# ESP32-P4 register map
Vendor: ESPRESSIF SYSTEMS (SHANGHAI) CO., LTD.; Series: ESP32 P-Series; File version: 3
CPU: RV32IMAFC r0p0, little endian, no MPU, FPU, 0 interrupt priority bits
Address unit: 32 bits
Registers are 32-bit, read-write, reset 0x0 unless marked. A register's access mark holds for its fields unless they carry their own. Offsets are from the block's base; [hi:lo] are bit positions; lines under a group give offsets from that group; {n}, {i} and the like mark numbered series.

## MCPWM0 — Motor Control Pulse-Width Modulation 0
Base 0x500C0000
Same registers: MCPWM1 0x500C1000
0x00 CLK_CFG — PWM clock prescaler register.
  [7:0] CLK_PRESCALE — Configures the prescaler value of clock, so that the period of PWM_clk = 6.25ns * (PWM_CLK_PRESCALE + 1).
{0x4+0x10*i} TIMER{i} (i=0..2) group — Cluster TIMER{i}, containing TIMER?_CFG0, TIMER?_CFG1, TIMER?_SYNC, TIMER?_STATUS
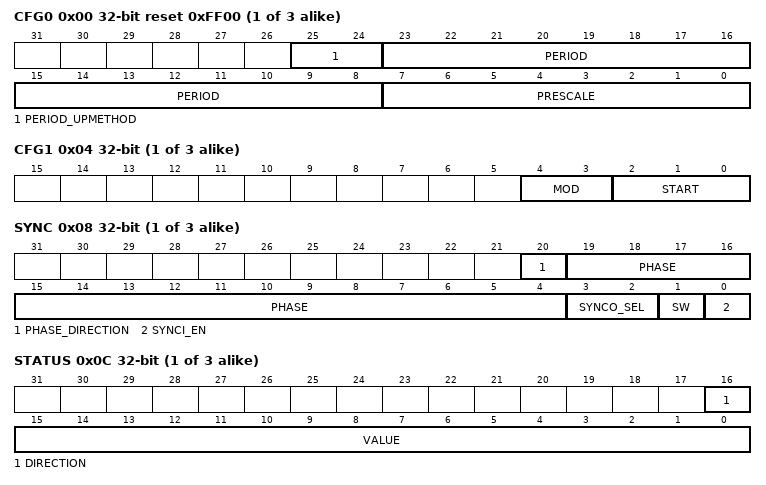
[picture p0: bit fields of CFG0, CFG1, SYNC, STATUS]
  0x00 CFG0 reset 0xFF00 — PWM timer0 period and update method configuration register.
    [25:24] PERIOD_UPMETHOD — Configures the update method for active register of PWM timer%s period.\\0: Immediate\\1: TEZ\\2: Sync\\3: TEZ or sync\\TEZ here and below means timer equal zero event
    [23:8] PERIOD — Configures the period shadow of PWM timer%s
    [7:0] PRESCALE — Configures the prescaler value of timer%s, so that the period of PT0_clk = Period of PWM_clk * (PWM_TIMER%s_PRESCALE + 1)
  0x04 CFG1 — PWM timer0 working mode and start/stop control register.
    [4:3] MOD — Configures the working mode of PWM timer%s.\\0: Freeze\\1: Increase mode\\2: Decrease mode\\3: Up-down mode
    [2:0] START — Configures whether or not to start/stop PWM timer%s.\\0: If PWM timer%s starts, then stops at TEZ\\1: If timer%s starts, then stops at TEP\\2: PWM timer%s starts and runs on\\3: Timer%s starts and stops at the next TEZ\\4: Timer0 starts and stops at the next TEP.\\TEP here and below means the event that happens when the timer equals to period
  0x08 SYNC — PWM timer0 sync function configuration register.
    [20] PHASE_DIRECTION — Configures the PWM timer%s's direction when timer%s mode is up-down mode.\\0: Increase\\1: Decrease
    [19:4] PHASE — Configures the phase for timer%s reload on sync event.
    [3:2] SYNCO_SEL — Configures the selection of PWM timer%s sync_out.\\0: Sync_in\\1: TEZ\\2: TEP\\3: Invalid, sync_out selects noting
    [1] SW — Configures the generation of software sync. Toggling this bit will trigger a software sync.
    [0] SYNCI_EN — Configures whether or not to enable timer%s reloading with phase on sync input event is enabled.\\0: Disable\\1: Enable
  0x0C STATUS ro — PWM timer0 status register.
    [16] DIRECTION — Represents current PWM timer%s counter direction.\\0: Increment\\1: Decrement
    [15:0] VALUE — Represents current PWM timer%s counter value.
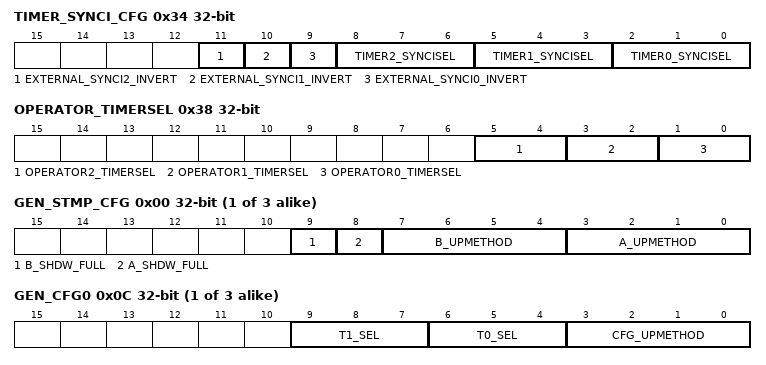
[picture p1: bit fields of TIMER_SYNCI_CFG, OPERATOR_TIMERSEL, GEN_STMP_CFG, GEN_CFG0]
0x34 TIMER_SYNCI_CFG — Synchronization input selection register for PWM timers.
  [11] EXTERNAL_SYNCI2_INVERT — Configures whether or not to invert SYNC2 from GPIO matrix.\\0: Not invert\\1: Invert
  [10] EXTERNAL_SYNCI1_INVERT — Configures whether or not to invert SYNC1 from GPIO matrix.\\0: Not invert\\1: Invert
  [9] EXTERNAL_SYNCI0_INVERT — Configures whether or not to invert SYNC0 from GPIO matrix.\\0: Not invert\\1: Invert
  [8:6] TIMER2_SYNCISEL — Configures the selection of sync input for PWM timer2.\\1: PWM timer0 sync_out\\2: PWM timer1 sync_out\\3: PWM timer2 sync_out\\4: SYNC0 from GPIO matrix\\5: SYNC1 from GPIO matrix\\6: SYNC2 from GPIO matrix\\Other values: No sync input selected
  [5:3] TIMER1_SYNCISEL — Configures the selection of sync input for PWM timer1.\\1: PWM timer0 sync_out\\2: PWM timer1 sync_out\\3: PWM timer2 sync_out\\4: SYNC0 from GPIO matrix\\5: SYNC1 from GPIO matrix\\6: SYNC2 from GPIO matrix\\Other values: No sync input selected
  [2:0] TIMER0_SYNCISEL — Configures the selection of sync input for PWM timer0.\\1: PWM timer0 sync_out\\2: PWM timer1 sync_out\\3: PWM timer2 sync_out\\4: SYNC0 from GPIO matrix\\5: SYNC1 from GPIO matrix\\6: SYNC2 from GPIO matrix\\Other values: No sync input selected
0x38 OPERATOR_TIMERSEL — PWM operator's timer select register
  [5:4] OPERATOR2_TIMERSEL — Configures which PWM timer will be the timing reference for PWM operator2.\\0: Timer0\\1: Timer1\\2: Timer2\\3: Invalid, will select timer2
  [3:2] OPERATOR1_TIMERSEL — Configures which PWM timer will be the timing reference for PWM operator1.\\0: Timer0\\1: Timer1\\2: Timer2\\3: Invalid, will select timer2
  [1:0] OPERATOR0_TIMERSEL — Configures which PWM timer will be the timing reference for PWM operator0.\\0: Timer0\\1: Timer1\\2: Timer2\\3: Invalid, will select timer2
{0x3C+0x38*i} CH{i} (i=0..2) group — Cluster CH{i}, containing GEN?_STMP_CFG, GEN?_TSTMP_A, GEN?_TSTMP_B, GEN?_CFG0, GEN?_FORCE, GEN?_A, GEN?_B, DT?_CFG, DT?_FED_CFG, DT?_RED_CFG, CARRIER?_CFG, FH?_CFG0, FH?_CFG1, FH?_STATUS
  0x00 GEN_STMP_CFG — Generator0 time stamp registers A and B transfer status and update method register
    [9] B_SHDW_FULL — Represents whether or not generator%s time stamp B's shadow reg is transferred.\\0: B's active reg has been updated with shadow register latest value.\\1: B's shadow reg is filled and waiting to be transferred to B's active reg
    [8] A_SHDW_FULL — Represents whether or not generator%s time stamp A's shadow reg is transferred.\\0: A's active reg has been updated with shadow register latest value.\\1: A's shadow reg is filled and waiting to be transferred to A's active reg
    [7:4] B_UPMETHOD — Configures the update method for PWM generator %s time stamp B's active register.\\0: Immediately\\Bit0 is set to 1: TEZ\\Bit1 is set to 1: TEP\\Bit2 is set to 1: Sync\\Bit3 is set to 1: Disable the update
    [3:0] A_UPMETHOD — Configures the update method for PWM generator %s time stamp A's active register.\\0: Immediately\\Bit0 is set to 1: TEZ\\Bit1 is set to 1: TEP\\Bit2 is set to 1: Sync\\Bit3 is set to 1: Disable the update
  0x04 GEN_TSTMP_A — Generator0 time stamp A's shadow register
    [15:0] A — Configures the value of PWM generator %s time stamp A's shadow register.
  0x08 GEN_TSTMP_B — Generator0 time stamp B's shadow register
    [15:0] B — Configures the value of PWM generator %s time stamp B's shadow register.
  0x0C GEN_CFG0 — Generator0 fault event T0 and T1 configuration register
    [9:7] T1_SEL — Configures source selection for PWM generator %s event_t1, take effect immediately.\\0: fault_event0\\1: fault_event1\\2: fault_event2\\3: sync_taken\\4: Invalid, Select nothing
    [6:4] T0_SEL — Configures source selection for PWM generator %s event_t0, take effect immediately.\\0: fault_event0\\1: fault_event1\\2: fault_event2\\3: sync_taken\\4: Invalid, Select nothing
    [3:0] CFG_UPMETHOD — Configures update method for PWM generator %s's active register.\\0: Immediately\\Bit0 is set to 1: TEZ\\Bit1 is set to 1: TEP\\Bit2 is set to 1: Sync\\Bit3 is set to 1: Disable the update
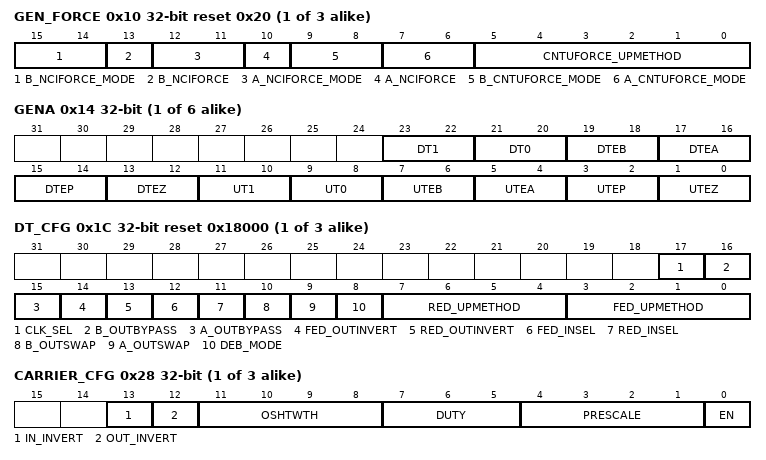
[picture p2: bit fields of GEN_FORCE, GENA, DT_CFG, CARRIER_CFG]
  0x10 GEN_FORCE reset 0x20 — Generator0 output signal force mode register.
    [15:14] B_NCIFORCE_MODE — Configures non-continuous immediate software force mode for PWM%s B.\\0: Disabled\\1: Low\\2: High\\3: Disabled
    [13] B_NCIFORCE — Configures the generation of non-continuous immediate software-force event for PWM%s B, a toggle will trigger a force event.
    [12:11] A_NCIFORCE_MODE — Configures non-continuous immediate software force mode for PWM%s A.\\0: Disabled\\1: Low\\2: High\\3: Disabled
    [10] A_NCIFORCE — Configures the generation of non-continuous immediate software-force event for PWM%s A, a toggle will trigger a force event.
    [9:8] B_CNTUFORCE_MODE — Configures continuous software force mode for PWM%s B.\\0: Disabled\\1: Low\\2: High\\3: Disabled
    [7:6] A_CNTUFORCE_MODE — Configures continuous software force mode for PWM%s A.\\0: Disabled\\1: Low\\2: High\\3: Disabled
    [5:0] CNTUFORCE_UPMETHOD — Configures update method for continuous software force of PWM generator%s.\\0: Immediately\\Bit0 is set to 1: TEZ\\Bit1 is set to 1: TEP\\Bit2 is set to 1: TEA\\Bit3 is set to 1: TEB\\Bit4 is set to 1: Sync\\Bit5 is set to 1: Disable update. TEA/B here and below means an event generated when the timer's value equals to that of register A/B.
  0x14 GEN{x} (x=A,B; step 0x4) — Actions triggered by events on PWMx{x}
    [23:22] DT1 — Configures action on PWM%s A triggered by event_t1 when timer decreasing.\\0: No change\\1: Low\\2: High\\3: Toggle
    [21:20] DT0 — Configures action on PWM%s A triggered by event_t0 when timer decreasing.\\0: No change\\1: Low\\2: High\\3: Toggle
    [19:18] DTEB — Configures action on PWM%s A triggered by event TEB when timer decreasing.\\0: No change\\1: Low\\2: High\\3: Toggle
    [17:16] DTEA — Configures action on PWM%s A triggered by event TEA when timer decreasing.\\0: No change\\1: Low\\2: High\\3: Toggle
    [15:14] DTEP — Configures action on PWM%s A triggered by event TEP when timer decreasing.\\0: No change\\1: Low\\2: High\\3: Toggle
    [13:12] DTEZ — Configures action on PWM%s A triggered by event TEZ when timer decreasing.\\0: No change\\1: Low\\2: High\\3: Toggle
    [11:10] UT1 — Configures action on PWM%s A triggered by event_t1 when timer increasing.\\0: No change\\1: Low\\2: High\\3: Toggle
    [9:8] UT0 — Configures action on PWM%s A triggered by event_t0 when timer increasing.\\0: No change\\1: Low\\2: High\\3: Toggle
    [7:6] UTEB — Configures action on PWM%s A triggered by event TEB when timer increasing.\\0: No change\\1: Low\\2: High\\3: Toggle
    [5:4] UTEA — Configures action on PWM%s A triggered by event TEA when timer increasing.\\0: No change\\1: Low\\2: High\\3: Toggle
    [3:2] UTEP — Configures action on PWM%s A triggered by event TEP when timer increasing.\\0: No change\\1: Low\\2: High\\3: Toggle
    [1:0] UTEZ — Configures action on PWM%s A triggered by event TEZ when timer increasing.\\0: No change\\1: Low\\2: High\\3: Toggle
  0x1C DT_CFG reset 0x18000 — Dead time configuration register
    [17] CLK_SEL — Configures dead time generator %s clock selection.\\0: PWM_clk\\1: PT_clk
    [16] B_OUTBYPASS — Configures S0 in table.
    [15] A_OUTBYPASS — Configures S1 in table.
    [14] FED_OUTINVERT — Configures S3 in table.
    [13] RED_OUTINVERT — Configures S2 in table.
    [12] FED_INSEL — Configures S5 in table.
    [11] RED_INSEL — Configures S4 in table.
    [10] B_OUTSWAP — Configures S7 in table.
    [9] A_OUTSWAP — Configures S6 in table.
    [8] DEB_MODE — Configures S8 in table, dual-edge B mode.\\0: fed/red take effect on different path separately\\1: fed/red take effect on B path, A out is in bypass or dulpB mode
    [7:4] RED_UPMETHOD — Configures update method for RED (rising edge delay) active register.\\0: Immediate\\Bit0 is set to 1: TEZ\\Bit1 is set to 1: TEP\\Bit2 is set to 1: Sync\\Bit3 is set to 1: Disable the update
    [3:0] FED_UPMETHOD — Configures update method for FED (Falling edge delay) active register.\\0: Immediate\\Bit0 is set to 1: TEZ\\Bit1 is set to 1: TEP\\Bit2 is set to 1: Sync\\Bit3 is set to 1: Disable the update
  0x20 DT_FED_CFG — Falling edge delay (FED) shadow register
    [15:0] FED — Configures shadow register for FED.
  0x24 DT_RED_CFG — Rising edge delay (RED) shadow register
    [15:0] RED — Configures shadow register for RED.
  0x28 CARRIER_CFG — Carrier0 configuration register
    [13] IN_INVERT — Configures whether or not to invert the input of PWM%s A and PWM%s B for this submodule.\\0: Normal\\1: Invert
    [12] OUT_INVERT — Configures whether or not to invert the output of PWM%s A and PWM%s B for this submodule.\\0: Normal\\1: Invert
    [11:8] OSHTWTH — Configures width of the first pulse. Measurement unit: Periods of the carrier.
    [7:5] DUTY — Configures carrier duty. Duty = PWM_CARRIER%s_DUTY / 8
    [4:1] PRESCALE — Configures the prescale value of PWM carrier%s clock (PC_clk), so that period of PC_clk = period of PWM_clk * (PWM_CARRIER%s_PRESCALE + 1)
    [0] EN — Configures whether or not to enable carrier%s.\\0: Bypassed\\1: Enabled
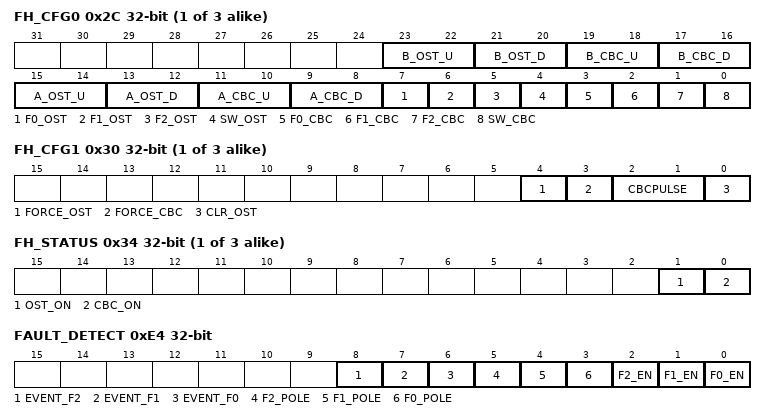
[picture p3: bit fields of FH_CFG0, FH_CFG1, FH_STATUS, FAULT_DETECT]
  0x2C FH_CFG0 — PWM0 A and PWM0 B trip events actions configuration register
    [23:22] B_OST_U — Configures one-shot mode action on PWM%s B when fault event occurs and timer is increasing.\\0: Do nothing\\1: Force low\\2: Force high\\3: Toggle
    [21:20] B_OST_D — Configures one-shot mode action on PWM%s B when fault event occurs and timer is decreasing.\\0: Do nothing\\1: Force low\\2: Force high\\3: Toggle
    [19:18] B_CBC_U — Configures cycle-by-cycle mode action on PWM%s B when fault event occurs and timer is increasing.\\0: Do nothing\\1: Force low\\2: Force high\\3: Toggle
    [17:16] B_CBC_D — Configures cycle-by-cycle mode action on PWM%s B when fault event occurs and timer is decreasing.\\0: Do nothing\\1: Force low\\2: Force high\\3: Toggle
    [15:14] A_OST_U — Configures one-shot mode action on PWM%s A when fault event occurs and timer is increasing.\\0: Do nothing\\1: Force low\\2: Force high\\3: Toggle
    [13:12] A_OST_D — Configures one-shot mode action on PWM%s A when fault event occurs and timer is decreasing.\\0: Do nothing\\1: Force low\\2: Force high\\3: Toggle
    [11:10] A_CBC_U — Configures cycle-by-cycle mode action on PWM%s A when fault event occurs and timer is increasing.\\0: Do nothing\\1: Force low\\2: Force high\\3: Toggle
    [9:8] A_CBC_D — Configures cycle-by-cycle mode action on PWM%s A when fault event occurs and timer is decreasing.\\0: Do nothing\\1: Force low\\2: Force high\\3: Toggle
    [7] F0_OST — Configures whether or not event_f0 will trigger one-shot mode action.\\0: Disable\\1: Enable
    [6] F1_OST — Configures whether or not event_f1 will trigger one-shot mode action.\\0: Disable\\1: Enable
    [5] F2_OST — Configures whether or not event_f2 will trigger one-shot mode action.\\0: Disable\\1: Enable
    [4] SW_OST — Configures whether or not to enable software force one-shot mode action.\\0: Disable\\1: Enable
    [3] F0_CBC — Configures whether or not event_f0 will trigger cycle-by-cycle mode action.\\0: Disable\\1: Enable
    [2] F1_CBC — Configures whether or not event_f1 will trigger cycle-by-cycle mode action.\\0: Disable\\1: Enable
    [1] F2_CBC — Configures whether or not event_f2 will trigger cycle-by-cycle mode action.\\0: Disable\\1: Enable
    [0] SW_CBC — Configures whether or not to enable software force cycle-by-cycle mode action.\\0: Disable\\1: Enable
  0x30 FH_CFG1 — Software triggers for fault handler actions configuration register
    [4] FORCE_OST — Configures the generation of software one-shot mode action. A toggle (software negate its value) triggers a one-shot mode action.
    [3] FORCE_CBC — Configures the generation of software cycle-by-cycle mode action. A toggle (software negate its value) triggers a cycle-by-cycle mode action.
    [2:1] CBCPULSE — Configures the refresh moment selection of cycle-by-cycle mode action.\\0: Select nothing, will not refresh\\Bit0 is set to 1: TEZ\\Bit1 is set to 1: TEP
    [0] CLR_OST — Configures the generation of software one-shot mode action clear. A toggle (software negate its value) triggers a clear for on going one-shot mode action.
  0x34 FH_STATUS ro — Fault events status register
    [1] OST_ON — Represents whether or not an one-shot mode action is on going.\\0:No action\\1: On going
    [0] CBC_ON — Represents whether or not an cycle-by-cycle mode action is on going.\\0:No action\\1: On going
0xE4 FAULT_DETECT access per field — Fault detection configuration and status register
  [8] EVENT_F2 ro — Represents whether or not an event_f2 is on going.\\0: No action\\1: On going
  [7] EVENT_F1 ro — Represents whether or not an event_f1 is on going.\\0: No action\\1: On going
  [6] EVENT_F0 ro — Represents whether or not an event_f0 is on going.\\0: No action\\1: On going
  [5] F2_POLE rw — Configures event_f2 trigger polarity on FAULT2 source from GPIO matrix.\\0: Level low\\1: Level high
  [4] F1_POLE rw — Configures event_f1 trigger polarity on FAULT1 source from GPIO matrix.\\0: Level low\\1: Level high
  [3] F0_POLE rw — Configures event_f0 trigger polarity on FAULT0 source from GPIO matrix.\\0: Level low\\1: Level high
  [2] F2_EN rw — Configures whether or not to enable event_f2 generation.\\0: Disable\\1: Enable
  [1] F1_EN rw — Configures whether or not to enable event_f1 generation.\\0: Disable\\1: Enable
  [0] F0_EN rw — Configures whether or not to enable event_f0 generation.\\0: Disable\\1: Enable
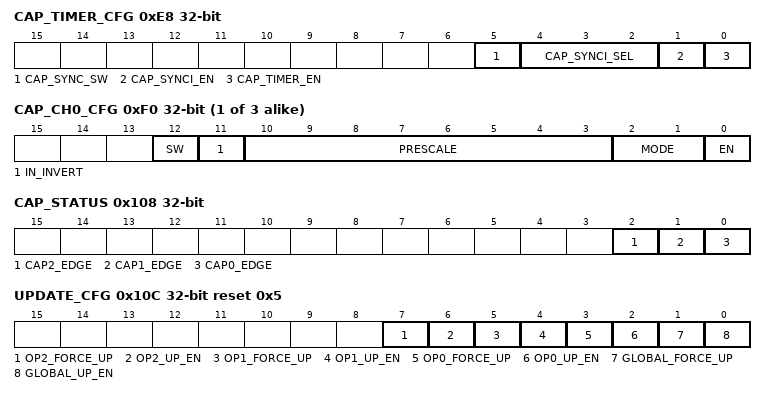
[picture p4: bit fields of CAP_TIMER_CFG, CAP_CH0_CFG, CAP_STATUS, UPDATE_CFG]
0xE8 CAP_TIMER_CFG access per field — Capture timer configuration register
  [5] CAP_SYNC_SW wo — Configures the generation of a capture timer sync when reg_cap_synci_en is 1.\\0: Invalid, No effect\\1: Trigger a capture timer sync, capture timer is loaded with value in phase register
  [4:2] CAP_SYNCI_SEL rw — Configures the selection of capture module sync input.\\0: None\\1: Timer0 sync_out\\2: Timer1 sync_out\\3: Timer2 sync_out\\4: SYNC0 from GPIO matrix\\5: SYNC1 from GPIO matrix\\6: SYNC2 from GPIO matrix\\7: None
  [1] CAP_SYNCI_EN rw — Configures whether or not to enable capture timer sync.\\0: Disable\\1: Enable
  [0] CAP_TIMER_EN rw — Configures whether or not to enable capture timer increment.\\0: Disable\\1: Enable
0xEC CAP_TIMER_PHASE — Capture timer sync phase register
  [31:0] CAP_PHASE — Configures phase value for capture timer sync operation.
{0xF0+4i} CAP_CH{i}_CFG (i=0..2) access per field — Capture channel {i} configuration register
  [12] SW wo — Configures the generation of software capture.\\0: Invalid, No effect\\1: Trigger a software forced capture on channel %s
  [11] IN_INVERT rw — Configures whether or not to invert CAP%s from GPIO matrix before prescale.\\0: Normal\\1: Invert
  [10:3] PRESCALE rw — Configures prescale value on possitive edge of CAP%s. Prescale value = PWM_CAP%s_PRESCALE + 1
  [2:1] MODE rw — Configures which edge of capture on channel %s after prescaling is used.\\0: None\\Bit0 is set to 1: Rnable capture on the negative edge\\Bit1 is set to 1: Enable capture on the positive edge
  [0] EN rw — Configures whether or not to enable capture on channel %s.\\0: Disable\\1: Enable
{0xFC+4i} CAP_CH{i} (i=0..2) ro — CAP{i} capture value register
  [31:0] VALUE — Represents value of last capture on CAP%s
0x108 CAP_STATUS ro — Last capture trigger edge information register
  [2] CAP2_EDGE — Represents edge of last capture trigger on channel2.\\0: Posedge\\1: Negedge
  [1] CAP1_EDGE — Represents edge of last capture trigger on channel1.\\0: Posedge\\1: Negedge
  [0] CAP0_EDGE — Represents edge of last capture trigger on channel0.\\0: Posedge\\1: Negedge
0x10C UPDATE_CFG reset 0x5 — Generator Update configuration register
  [7] OP2_FORCE_UP — Configures the generation of forced update for active registers in PWM operator2. A toggle (software invert its value) will trigger a forced update. Valid only when MCPWM_GLOBAL_UP_EN and MCPWM_OP2_UP_EN are both set to 1.
  [6] OP2_UP_EN — Configures whether or not to enable update of active registers in PWM operator2. Valid only when PWM_GLOBAL_UP_EN is set to 1.\\0: Disable\\1: Enable
  [5] OP1_FORCE_UP — Configures the generation of forced update for active registers in PWM operator1. A toggle (software invert its value) will trigger a forced update. Valid only when MCPWM_GLOBAL_UP_EN and MCPWM_OP1_UP_EN are both set to 1.
  [4] OP1_UP_EN — Configures whether or not to enable update of active registers in PWM operator1. Valid only when PWM_GLOBAL_UP_EN is set to 1.\\0: Disable\\1: Enable
  [3] OP0_FORCE_UP — Configures the generation of forced update for active registers in PWM operator0. A toggle (software invert its value) will trigger a forced update. Valid only when MCPWM_GLOBAL_UP_EN and MCPWM_OP0_UP_EN are both set to 1.
  [2] OP0_UP_EN — Configures whether or not to enable update of active registers in PWM operator0. Valid only when PWM_GLOBAL_UP_EN is set to 1.\\0: Disable\\1: Enable
  [1] GLOBAL_FORCE_UP — Configures the generation of global forced update for all active registers in MCPWM module. A toggle (software invert its value) will trigger a global forced update. Valid only when MCPWM_GLOBAL_UP_EN and MCPWM_OP0/1/2_UP_EN are both set to 1.
  [0] GLOBAL_UP_EN — Configures whether or not to enable global update for all active registers in MCPWM module.\\0: Disable\\1: Enable
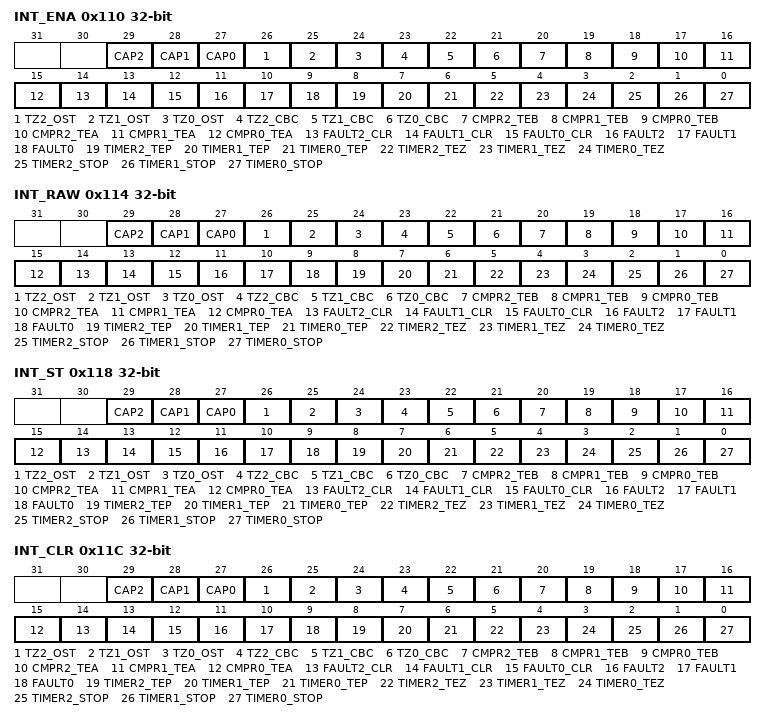
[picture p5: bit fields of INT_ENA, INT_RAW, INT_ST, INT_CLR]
0x110 INT_ENA — Interrupt enable register
  [29] CAP2 — Enable bit: Write 1 to enable the interrupt triggered by capture on CAP2.
  [28] CAP1 — Enable bit: Write 1 to enable the interrupt triggered by capture on CAP1.
  [27] CAP0 — Enable bit: Write 1 to enable the interrupt triggered by capture on CAP0.
  [26] TZ2_OST — Enable bit: Write 1 to enable the interrupt triggered by a one-shot mode action on PWM2.
  [25] TZ1_OST — Enable bit: Write 1 to enable the interrupt triggered by a one-shot mode action on PWM1.
  [24] TZ0_OST — Enable bit: Write 1 to enable the interrupt triggered by a one-shot mode action on PWM0.
  [23] TZ2_CBC — Enable bit: Write 1 to enable the interrupt triggered by a cycle-by-cycle mode action on PWM2.
  [22] TZ1_CBC — Enable bit: Write 1 to enable the interrupt triggered by a cycle-by-cycle mode action on PWM1.
  [21] TZ0_CBC — Enable bit: Write 1 to enable the interrupt triggered by a cycle-by-cycle mode action on PWM0.
  [20] CMPR2_TEB — Enable bit: Write 1 to enable the interrupt triggered by a PWM operator 2 TEB event.
  [19] CMPR1_TEB — Enable bit: Write 1 to enable the interrupt triggered by a PWM operator 1 TEB event.
  [18] CMPR0_TEB — Enable bit: Write 1 to enable the interrupt triggered by a PWM operator 0 TEB event.
  [17] CMPR2_TEA — Enable bit: Write 1 to enable the interrupt triggered by a PWM operator 2 TEA event.
  [16] CMPR1_TEA — Enable bit: Write 1 to enable the interrupt triggered by a PWM operator 1 TEA event.
  [15] CMPR0_TEA — Enable bit: Write 1 to enable the interrupt triggered by a PWM operator 0 TEA event.
  [14] FAULT2_CLR — Enable bit: Write 1 to enable the interrupt triggered when event_f2 clears.
  [13] FAULT1_CLR — Enable bit: Write 1 to enable the interrupt triggered when event_f1 clears.
  [12] FAULT0_CLR — Enable bit: Write 1 to enable the interrupt triggered when event_f0 clears.
  [11] FAULT2 — Enable bit: Write 1 to enable the interrupt triggered when event_f2 starts.
  [10] FAULT1 — Enable bit: Write 1 to enable the interrupt triggered when event_f1 starts.
  [9] FAULT0 — Enable bit: Write 1 to enable the interrupt triggered when event_f0 starts.
  [8] TIMER2_TEP — Enable bit: Write 1 to enable the interrupt triggered by a PWM timer 2 TEP event.
  [7] TIMER1_TEP — Enable bit: Write 1 to enable the interrupt triggered by a PWM timer 1 TEP event.
  [6] TIMER0_TEP — Enable bit: Write 1 to enable the interrupt triggered by a PWM timer 0 TEP event.
  [5] TIMER2_TEZ — Enable bit: Write 1 to enable the interrupt triggered by a PWM timer 2 TEZ event.
  [4] TIMER1_TEZ — Enable bit: Write 1 to enable the interrupt triggered by a PWM timer 1 TEZ event.
  [3] TIMER0_TEZ — Enable bit: Write 1 to enable the interrupt triggered by a PWM timer 0 TEZ event.
  [2] TIMER2_STOP — Enable bit: Write 1 to enable the interrupt triggered when the timer 2 stops.
  [1] TIMER1_STOP — Enable bit: Write 1 to enable the interrupt triggered when the timer 1 stops.
  [0] TIMER0_STOP — Enable bit: Write 1 to enable the interrupt triggered when the timer 0 stops.
0x114 INT_RAW — Interrupt raw status register
  [29] CAP2 — Raw status bit: The raw interrupt status of the interrupt triggered by capture on CAP2.
  [28] CAP1 — Raw status bit: The raw interrupt status of the interrupt triggered by capture on CAP1.
  [27] CAP0 — Raw status bit: The raw interrupt status of the interrupt triggered by capture on CAP0.
  [26] TZ2_OST — Raw status bit: The raw interrupt status of the interrupt triggered by a one-shot mode action on PWM2.
  [25] TZ1_OST — Raw status bit: The raw interrupt status of the interrupt triggered by a one-shot mode action on PWM1.
  [24] TZ0_OST — Raw status bit: The raw interrupt status of the interrupt triggered by a one-shot mode action on PWM0.
  [23] TZ2_CBC — Raw status bit: The raw interrupt status of the interrupt triggered by a cycle-by-cycle mode action on PWM2.
  [22] TZ1_CBC — Raw status bit: The raw interrupt status of the interrupt triggered by a cycle-by-cycle mode action on PWM1.
  [21] TZ0_CBC — Raw status bit: The raw interrupt status of the interrupt triggered by a cycle-by-cycle mode action on PWM0.
  [20] CMPR2_TEB — Raw status bit: The raw interrupt status of the interrupt triggered by a PWM operator 2 TEB event
  [19] CMPR1_TEB — Raw status bit: The raw interrupt status of the interrupt triggered by a PWM operator 1 TEB event
  [18] CMPR0_TEB — Raw status bit: The raw interrupt status of the interrupt triggered by a PWM operator 0 TEB event
  [17] CMPR2_TEA — Raw status bit: The raw interrupt status of the interrupt triggered by a PWM operator 2 TEA event
  [16] CMPR1_TEA — Raw status bit: The raw interrupt status of the interrupt triggered by a PWM operator 1 TEA event
  [15] CMPR0_TEA — Raw status bit: The raw interrupt status of the interrupt triggered by a PWM operator 0 TEA event
  [14] FAULT2_CLR — Raw status bit: The raw interrupt status of the interrupt triggered when event_f2 clears.
  [13] FAULT1_CLR — Raw status bit: The raw interrupt status of the interrupt triggered when event_f1 clears.
  [12] FAULT0_CLR — Raw status bit: The raw interrupt status of the interrupt triggered when event_f0 clears.
  [11] FAULT2 — Raw status bit: The raw interrupt status of the interrupt triggered when event_f2 starts.
  [10] FAULT1 — Raw status bit: The raw interrupt status of the interrupt triggered when event_f1 starts.
  [9] FAULT0 — Raw status bit: The raw interrupt status of the interrupt triggered when event_f0 starts.
  [8] TIMER2_TEP — Raw status bit: The raw interrupt status of the interrupt triggered by a PWM timer 2 TEP event.
  [7] TIMER1_TEP — Raw status bit: The raw interrupt status of the interrupt triggered by a PWM timer 1 TEP event.
  [6] TIMER0_TEP — Raw status bit: The raw interrupt status of the interrupt triggered by a PWM timer 0 TEP event.
  [5] TIMER2_TEZ — Raw status bit: The raw interrupt status of the interrupt triggered by a PWM timer 2 TEZ event.
  [4] TIMER1_TEZ — Raw status bit: The raw interrupt status of the interrupt triggered by a PWM timer 1 TEZ event.
  [3] TIMER0_TEZ — Raw status bit: The raw interrupt status of the interrupt triggered by a PWM timer 0 TEZ event.
  [2] TIMER2_STOP — Raw status bit: The raw interrupt status of the interrupt triggered when the timer 2 stops.
  [1] TIMER1_STOP — Raw status bit: The raw interrupt status of the interrupt triggered when the timer 1 stops.
  [0] TIMER0_STOP — Raw status bit: The raw interrupt status of the interrupt triggered when the timer 0 stops.
0x118 INT_ST ro — Interrupt masked status register
  [29] CAP2 — Masked status bit: The masked interrupt status of the interrupt triggered by capture on CAP2.
  [28] CAP1 — Masked status bit: The masked interrupt status of the interrupt triggered by capture on CAP1.
  [27] CAP0 — Masked status bit: The masked interrupt status of the interrupt triggered by capture on CAP0.
  [26] TZ2_OST — Masked status bit: The masked interrupt status of the interrupt triggered by a one-shot mode action on PWM2.
  [25] TZ1_OST — Masked status bit: The masked interrupt status of the interrupt triggered by a one-shot mode action on PWM1.
  [24] TZ0_OST — Masked status bit: The masked interrupt status of the interrupt triggered by a one-shot mode action on PWM0.
  [23] TZ2_CBC — Masked status bit: The masked interrupt status of the interrupt triggered by a cycle-by-cycle mode action on PWM2.
  [22] TZ1_CBC — Masked status bit: The masked interrupt status of the interrupt triggered by a cycle-by-cycle mode action on PWM1.
  [21] TZ0_CBC — Masked status bit: The masked interrupt status of the interrupt triggered by a cycle-by-cycle mode action on PWM0.
  [20] CMPR2_TEB — Masked status bit: The masked interrupt status of the interrupt triggered by a PWM operator 2 TEB event
  [19] CMPR1_TEB — Masked status bit: The masked interrupt status of the interrupt triggered by a PWM operator 1 TEB event
  [18] CMPR0_TEB — Masked status bit: The masked interrupt status of the interrupt triggered by a PWM operator 0 TEB event
  [17] CMPR2_TEA — Masked status bit: The masked interrupt status of the interrupt triggered by a PWM operator 2 TEA event
  [16] CMPR1_TEA — Masked status bit: The masked interrupt status of the interrupt triggered by a PWM operator 1 TEA event
  [15] CMPR0_TEA — Masked status bit: The masked interrupt status of the interrupt triggered by a PWM operator 0 TEA event
  [14] FAULT2_CLR — Masked status bit: The masked interrupt status of the interrupt triggered when event_f2 clears.
  [13] FAULT1_CLR — Masked status bit: The masked interrupt status of the interrupt triggered when event_f1 clears.
  [12] FAULT0_CLR — Masked status bit: The masked interrupt status of the interrupt triggered when event_f0 clears.
  [11] FAULT2 — Masked status bit: The masked interrupt status of the interrupt triggered when event_f2 starts.
  [10] FAULT1 — Masked status bit: The masked interrupt status of the interrupt triggered when event_f1 starts.
  [9] FAULT0 — Masked status bit: The masked interrupt status of the interrupt triggered when event_f0 starts.
  [8] TIMER2_TEP — Masked status bit: The masked interrupt status of the interrupt triggered by a PWM timer 2 TEP event.
  [7] TIMER1_TEP — Masked status bit: The masked interrupt status of the interrupt triggered by a PWM timer 1 TEP event.
  [6] TIMER0_TEP — Masked status bit: The masked interrupt status of the interrupt triggered by a PWM timer 0 TEP event.
  [5] TIMER2_TEZ — Masked status bit: The masked interrupt status of the interrupt triggered by a PWM timer 2 TEZ event.
  [4] TIMER1_TEZ — Masked status bit: The masked interrupt status of the interrupt triggered by a PWM timer 1 TEZ event.
  [3] TIMER0_TEZ — Masked status bit: The masked interrupt status of the interrupt triggered by a PWM timer 0 TEZ event.
  [2] TIMER2_STOP — Masked status bit: The masked interrupt status of the interrupt triggered when the timer 2 stops.
  [1] TIMER1_STOP — Masked status bit: The masked interrupt status of the interrupt triggered when the timer 1 stops.
  [0] TIMER0_STOP — Masked status bit: The masked interrupt status of the interrupt triggered when the timer 0 stops.
0x11C INT_CLR wo — Interrupt clear register
  [29] CAP2 write-1-clears — Clear bit: Write 1 to clear the interrupt triggered by capture on CAP2.
  [28] CAP1 write-1-clears — Clear bit: Write 1 to clear the interrupt triggered by capture on CAP1.
  [27] CAP0 write-1-clears — Clear bit: Write 1 to clear the interrupt triggered by capture on CAP0.
  [26] TZ2_OST write-1-clears — Clear bit: Write 1 to clear the interrupt triggered by a one-shot mode action on PWM2.
  [25] TZ1_OST write-1-clears — Clear bit: Write 1 to clear the interrupt triggered by a one-shot mode action on PWM1.
  [24] TZ0_OST write-1-clears — Clear bit: Write 1 to clear the interrupt triggered by a one-shot mode action on PWM0.
  [23] TZ2_CBC write-1-clears — Clear bit: Write 1 to clear the interrupt triggered by a cycle-by-cycle mode action on PWM2.
  [22] TZ1_CBC write-1-clears — Clear bit: Write 1 to clear the interrupt triggered by a cycle-by-cycle mode action on PWM1.
  [21] TZ0_CBC write-1-clears — Clear bit: Write 1 to clear the interrupt triggered by a cycle-by-cycle mode action on PWM0.
  [20] CMPR2_TEB write-1-clears — Clear bit: Write 1 to clear the interrupt triggered by a PWM operator 2 TEB event
  [19] CMPR1_TEB write-1-clears — Clear bit: Write 1 to clear the interrupt triggered by a PWM operator 1 TEB event
  [18] CMPR0_TEB write-1-clears — Clear bit: Write 1 to clear the interrupt triggered by a PWM operator 0 TEB event
  [17] CMPR2_TEA write-1-clears — Clear bit: Write 1 to clear the interrupt triggered by a PWM operator 2 TEA event
  [16] CMPR1_TEA write-1-clears — Clear bit: Write 1 to clear the interrupt triggered by a PWM operator 1 TEA event
  [15] CMPR0_TEA write-1-clears — Clear bit: Write 1 to clear the interrupt triggered by a PWM operator 0 TEA event
  [14] FAULT2_CLR write-1-clears — Clear bit: Write 1 to clear the interrupt triggered when event_f2 clears.
  [13] FAULT1_CLR write-1-clears — Clear bit: Write 1 to clear the interrupt triggered when event_f1 clears.
  [12] FAULT0_CLR write-1-clears — Clear bit: Write 1 to clear the interrupt triggered when event_f0 clears.
  [11] FAULT2 write-1-clears — Clear bit: Write 1 to clear the interrupt triggered when event_f2 starts.
  [10] FAULT1 write-1-clears — Clear bit: Write 1 to clear the interrupt triggered when event_f1 starts.
  [9] FAULT0 write-1-clears — Clear bit: Write 1 to clear the interrupt triggered when event_f0 starts.
  [8] TIMER2_TEP write-1-clears — Clear bit: Write 1 to clear the interrupt triggered by a PWM timer 2 TEP event.
  [7] TIMER1_TEP write-1-clears — Clear bit: Write 1 to clear the interrupt triggered by a PWM timer 1 TEP event.
  [6] TIMER0_TEP write-1-clears — Clear bit: Write 1 to clear the interrupt triggered by a PWM timer 0 TEP event.
  [5] TIMER2_TEZ write-1-clears — Clear bit: Write 1 to clear the interrupt triggered by a PWM timer 2 TEZ event.
  [4] TIMER1_TEZ write-1-clears — Clear bit: Write 1 to clear the interrupt triggered by a PWM timer 1 TEZ event.
  [3] TIMER0_TEZ write-1-clears — Clear bit: Write 1 to clear the interrupt triggered by a PWM timer 0 TEZ event.
  [2] TIMER2_STOP write-1-clears — Clear bit: Write 1 to clear the interrupt triggered when the timer 2 stops.
  [1] TIMER1_STOP write-1-clears — Clear bit: Write 1 to clear the interrupt triggered when the timer 1 stops.
  [0] TIMER0_STOP write-1-clears — Clear bit: Write 1 to clear the interrupt triggered when the timer 0 stops.
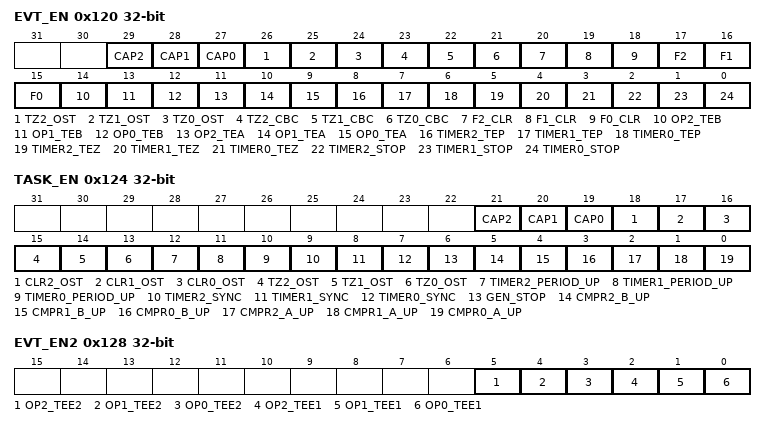
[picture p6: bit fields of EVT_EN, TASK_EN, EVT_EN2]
0x120 EVT_EN — Event enable register
  [29] CAP2 — Configures whether or not to enable capture2 event generate.\\0: Disable\\1: Enable
  [28] CAP1 — Configures whether or not to enable capture1 event generate.\\0: Disable\\1: Enable
  [27] CAP0 — Configures whether or not to enable capture0 event generate.\\0: Disable\\1: Enable
  [26] TZ2_OST — Configures whether or not to enable one-shot trip2 event generate.\\0: Disable\\1: Enable
  [25] TZ1_OST — Configures whether or not to enable one-shot trip1 event generate.\\0: Disable\\1: Enable
  [24] TZ0_OST — Configures whether or not to enable one-shot trip0 event generate.\\0: Disable\\1: Enable
  [23] TZ2_CBC — Configures whether or not to enable cycle-by-cycle trip2 event generate.\\0: Disable\\1: Enable
  [22] TZ1_CBC — Configures whether or not to enable cycle-by-cycle trip1 event generate.\\0: Disable\\1: Enable
  [21] TZ0_CBC — Configures whether or not to enable cycle-by-cycle trip0 event generate.\\0: Disable\\1: Enable
  [20] F2_CLR — Configures whether or not to enable fault2 clear event generate.\\0: Disable\\1: Enable
  [19] F1_CLR — Configures whether or not to enable fault1 clear event generate.\\0: Disable\\1: Enable
  [18] F0_CLR — Configures whether or not to enable fault0 clear event generate.\\0: Disable\\1: Enable
  [17] F2 — Configures whether or not to enable fault2 event generate.\\0: Disable\\1: Enable
  [16] F1 — Configures whether or not to enable fault1 event generate.\\0: Disable\\1: Enable
  [15] F0 — Configures whether or not to enable fault0 event generate.\\0: Disable\\1: Enable
  [14] OP2_TEB — Configures whether or not to enable PWM generator2 timer equal b event generate.\\0: Disable\\1: Enable
  [13] OP1_TEB — Configures whether or not to enable PWM generator1 timer equal b event generate.\\0: Disable\\1: Enable
  [12] OP0_TEB — Configures whether or not to enable PWM generator0 timer equal b event generate.\\0: Disable\\1: Enable
  [11] OP2_TEA — Configures whether or not to enable PWM generator2 timer equal a event generate.\\0: Disable\\1: Enable
  [10] OP1_TEA — Configures whether or not to enable PWM generator1 timer equal a event generate.\\0: Disable\\1: Enable
  [9] OP0_TEA — Configures whether or not to enable PWM generator0 timer equal a event generate.\\0: Disable\\1: Enable
  [8] TIMER2_TEP — Configures whether or not to enable timer2 equal period event generate.\\0: Disable\\1: Enable
  [7] TIMER1_TEP — Configures whether or not to enable timer1 equal period event generate.\\0: Disable\\1: Enable
  [6] TIMER0_TEP — Configures whether or not to enable timer0 equal period event generate.\\0: Disable\\1: Enable
  [5] TIMER2_TEZ — Configures whether or not to enable timer2 equal zero event generate.\\0: Disable\\1: Enable
  [4] TIMER1_TEZ — Configures whether or not to enable timer1 equal zero event generate.\\0: Disable\\1: Enable
  [3] TIMER0_TEZ — Configures whether or not to enable timer0 equal zero event generate.\\0: Disable\\1: Enable
  [2] TIMER2_STOP — Configures whether or not to enable timer2 stop event generate.\\0: Disable\\1: Enable
  [1] TIMER1_STOP — Configures whether or not to enable timer1 stop event generate.\\0: Disable\\1: Enable
  [0] TIMER0_STOP — Configures whether or not to enable timer0 stop event generate.\\0: Disable\\1: Enable
0x124 TASK_EN — Task enable register
  [21] CAP2 — Configures whether or not to enable capture2 task receive.\\0: Disable\\1: Enable
  [20] CAP1 — Configures whether or not to enable capture1 task receive.\\0: Disable\\1: Enable
  [19] CAP0 — Configures whether or not to enable capture0 task receive.\\0: Disable\\1: Enable
  [18] CLR2_OST — Configures whether or not to enable one shot trip2 clear task receive.\\0: Disable\\1: Enable
  [17] CLR1_OST — Configures whether or not to enable one shot trip1 clear task receive.\\0: Disable\\1: Enable
  [16] CLR0_OST — Configures whether or not to enable one shot trip0 clear task receive.\\0: Disable\\1: Enable
  [15] TZ2_OST — Configures whether or not to enable one shot trip2 task receive.\\0: Disable\\1: Enable
  [14] TZ1_OST — Configures whether or not to enable one shot trip1 task receive.\\0: Disable\\1: Enable
  [13] TZ0_OST — Configures whether or not to enable one shot trip0 task receive.\\0: Disable\\1: Enable
  [12] TIMER2_PERIOD_UP — Configures whether or not to enable timer2 period update task receive.\\0: Disable\\1: Enable
  [11] TIMER1_PERIOD_UP — Configures whether or not to enable timer1 period update task receive.\\0: Disable\\1: Enable
  [10] TIMER0_PERIOD_UP — Configures whether or not to enable timer0 period update task receive.\\0: Disable\\1: Enable
  [9] TIMER2_SYNC — Configures whether or not to enable timer2 sync task receive.\\0: Disable\\1: Enable
  [8] TIMER1_SYNC — Configures whether or not to enable timer1 sync task receive.\\0: Disable\\1: Enable
  [7] TIMER0_SYNC — Configures whether or not to enable timer0 sync task receive.\\0: Disable\\1: Enable
  [6] GEN_STOP — Configures whether or not to enable all PWM generate stop task receive.\\0: Disable\\1: Enable
  [5] CMPR2_B_UP — Configures whether or not to enable PWM generator2 timer stamp B's shadow register update task receive.\\0: Disable\\1: Enable
  [4] CMPR1_B_UP — Configures whether or not to enable PWM generator1 timer stamp B's shadow register update task receive.\\0: Disable\\1: Enable
  [3] CMPR0_B_UP — Configures whether or not to enable PWM generator0 timer stamp B's shadow register update task receive.\\0: Disable\\1: Enable
  [2] CMPR2_A_UP — Configures whether or not to enable PWM generator2 timer stamp A's shadow register update task receive.\\0: Disable\\1: Enable
  [1] CMPR1_A_UP — Configures whether or not to enable PWM generator1 timer stamp A's shadow register update task receive.\\0: Disable\\1: Enable
  [0] CMPR0_A_UP — Configures whether or not to enable PWM generator0 timer stamp A's shadow register update task receive.\\0: Disable\\1: Enable
0x128 EVT_EN2 — Event enable register2
  [5] OP2_TEE2 — Configures whether or not to enable PWM generator2 timer equal OP2_TSTMP_E2_REG event generate.\\0: Disable\\1: Enable
  [4] OP1_TEE2 — Configures whether or not to enable PWM generator1 timer equal OP1_TSTMP_E2_REG event generate.\\0: Disable\\1: Enable
  [3] OP0_TEE2 — Configures whether or not to enable PWM generator0 timer equal OP0_TSTMP_E2_REG event generate.\\0: Disable\\1: Enable
  [2] OP2_TEE1 — Configures whether or not to enable PWM generator2 timer equal OP2_TSTMP_E1_REG event generate.\\0: Disable\\1: Enable
  [1] OP1_TEE1 — Configures whether or not to enable PWM generator1 timer equal OP1_TSTMP_E1_REG event generate.\\0: Disable\\1: Enable
  [0] OP0_TEE1 — Configures whether or not to enable PWM generator0 timer equal OP0_TSTMP_E1_REG event generate.\\0: Disable\\1: Enable
{0x12C+8i} OP{i}_TSTMP_E1 (i=0..2) — Generator{i} timer stamp E1 value register
  [15:0] OP_TSTMP_E1 — Configures generator%s timer stamp E1 value register
{0x130+8i} OP{i}_TSTMP_E2 (i=0..2) — Generator{i} timer stamp E2 value register
  [15:0] OP_TSTMP_E2 — Configures generator%s timer stamp E2 value register
0x144 CLK — Global configuration register
  [0] EN — Configures whether or not to open register clock gate.\\0: Open the clock gate only when application writes registers\\1: Force open the clock gate for register
0x148 VERSION reset 0x2212290
  [27:0] DATE — Configures the version.
